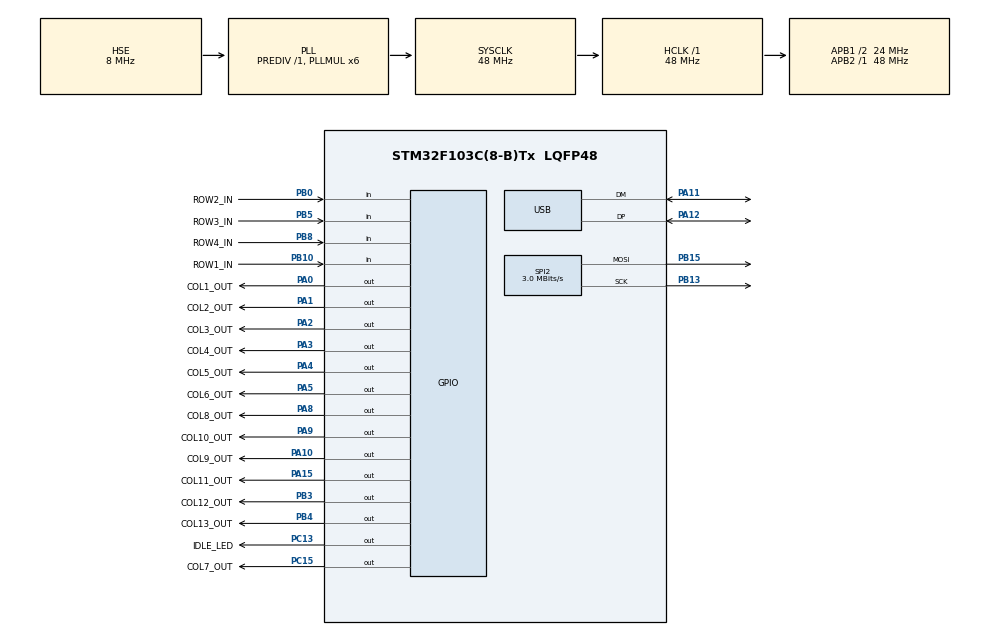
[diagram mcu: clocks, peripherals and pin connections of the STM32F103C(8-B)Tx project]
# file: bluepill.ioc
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Mcu.Family=STM32F1
Dma.SPI2_TX.0.MemInc=DMA_MINC_ENABLE
USB_DEVICE.CLASS_NAME_FS=HID
NVIC.DMA1_Channel5_IRQn=true\:0\:0\:false\:false\:true\:false\:true
PB10.GPIO_PuPd=GPIO_PULLDOWN
SPI2.VirtualType=VM_MASTER
PA11.Mode=Device
PB0.GPIO_Label=ROW2_IN
PB13.Signal=SPI2_SCK
PB15.Signal=SPI2_MOSI
PC15-OSC32_OUT.GPIO_Label=COL7_OUT
Dma.SPI2_TX.0.Instance=DMA1_Channel5
RCC.SYSCLKSource=RCC_SYSCLKSOURCE_PLLCLK
ProjectManager.StackSize=0x400
PD1-OSC_OUT.Signal=RCC_OSC_OUT
Dma.SPI2_TX.0.MemDataAlignment=DMA_MDATAALIGN_BYTE
USB_DEVICE.MANUFACTURER_STRING=Disciplined Design
USB_DEVICE.PID_HID_FS=0x0666
PA15.GPIO_Label=COL11_OUT
PA12.Signal=USB_DP
SPI2.CLKPolarity=SPI_POLARITY_LOW
RCC.HCLKFreq_Value=48000000
RCC.APB2TimFreq_Value=48000000
Dma.SPI2_TX.0.Mode=DMA_NORMAL
RCC.AHBFreq_Value=48000000
SPI2.BaudRatePrescaler=SPI_BAUDRATEPRESCALER_8
RCC.PLLMUL=RCC_PLL_MUL6
PA14.Mode=Serial_Wire
PA10.GPIO_Label=COL9_OUT
SPI2.CalculateBaudRate=3.0 MBits/s
PA8.Signal=GPIO_Output
Mcu.Package=LQFP48
SPI2.Mode=SPI_MODE_MASTER
PA2.GPIO_Label=COL3_OUT
PA10.Signal=GPIO_Output
PA15.Signal=GPIO_Output
Dma.SPI2_TX.0.PeriphInc=DMA_PINC_DISABLE
PB5.GPIO_Label=ROW3_IN
RCC.APB1TimFreq_Value=48000000
SPI2.Direction=SPI_DIRECTION_2LINES
PB13.Mode=TX_Only_Simplex_Unidirect_Master
Dma.Request0=SPI2_TX
PA4.GPIO_Label=COL5_OUT
PB4.Signal=GPIO_Output
PA3.Signal=GPIO_Output
PB3.GPIO_Label=COL12_OUT
PD1-OSC_OUT.Mode=HSE-External-Oscillator
USB_DEVICE.VirtualModeFS=Hid_FS
PA9.GPIO_Label=COL10_OUT
PB8.GPIO_PuPd=GPIO_PULLDOWN
USB_DEVICE.PRODUCT_STRING_HID_FS=DD Keyboard
PC13-TAMPER-RTC.Signal=GPIO_Output
PD0-OSC_IN.Signal=RCC_OSC_IN
RCC.APB1CLKDivider=RCC_HCLK_DIV2
PA0-WKUP.GPIO_Label=COL1_OUT
PA0-WKUP.Signal=GPIO_Output
PA13.Signal=SYS_JTMS-SWDIO
PB8.GPIO_Label=ROW4_IN
PA8.GPIO_Label=COL8_OUT
USB_DEVICE.VID=0xFEED
ProjectManager.TargetToolchain=Makefile
PB10.GPIO_Label=ROW1_IN
PA9.Signal=GPIO_Output
RCC.USBFreq_Value=48000000
PC15-OSC32_OUT.Signal=GPIO_Output
PA1.Signal=GPIO_Output
PD0-OSC_IN.Mode=HSE-External-Oscillator
PB10.Signal=GPIO_Input
PA5.Signal=GPIO_Output
board=bluepill
PC13-TAMPER-RTC.GPIO_Label=IDLE_LED
PB15.Mode=TX_Only_Simplex_Unidirect_Master
VP_USB_DEVICE_VS_USB_DEVICE_HID_FS.Mode=HID_FS
RCC.APB2Freq_Value=48000000
PB4.GPIO_Label=COL13_OUT
Dma.SPI2_TX.0.PeriphDataAlignment=DMA_PDATAALIGN_BYTE
NVIC.USB_LP_CAN1_RX0_IRQn=true\:0\:0\:false\:false\:true\:false\:true
PA1.GPIO_Label=COL2_OUT
PA13.Mode=Serial_Wire
Mcu.Name=STM32F103C(8-B)Tx
PA2.Signal=GPIO_Output
PB3.Signal=GPIO_Output
PA4.Signal=GPIO_Output
Dma.SPI2_TX.0.Priority=DMA_PRIORITY_HIGH
RCC.SYSCLKFreq_VALUE=48000000
PB5.Signal=GPIO_Input
PA12.Mode=Device
PA5.GPIO_Label=COL6_OUT
PB5.GPIO_PuPd=GPIO_PULLDOWN
PA11.Signal=USB_DM
PA14.Signal=SYS_JTCK-SWCLK
ProjectManager.HeapSize=0x200
NVIC.PriorityGroup=NVIC_PRIORITYGROUP_4
PB8.Signal=GPIO_Input
Dma.SPI2_TX.0.Direction=DMA_MEMORY_TO_PERIPH
RCC.APB1Freq_Value=24000000
PB0.Signal=GPIO_Input
USB_DEVICE.VirtualMode=Hid
PB0.GPIO_PuPd=GPIO_PULLDOWN
PA3.GPIO_Label=COL4_OUT

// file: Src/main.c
/* USER CODE BEGIN Header */
/**
  ******************************************************************************
  * @file           : main.c
  * @brief          : Main program body
  ******************************************************************************
  * @attention
  *
  * <h2><center>&copy; Copyright (c) 2019 STMicroelectronics.
  * All rights reserved.</center></h2>
  *
  * This software component is licensed by ST under BSD 3-Clause license,
  * the "License"; You may not use this file except in compliance with the
  * License. You may obtain a copy of the License at:
  *                        opensource.org/licenses/BSD-3-Clause
  *
  ******************************************************************************
  */
/* USER CODE END Header */
#include "main.h"
#include "usb_device.h"

/* USER CODE BEGIN Includes */
#include "esm/esm.h"
/* USER CODE END Includes */

SPI_HandleTypeDef hspi2;
DMA_HandleTypeDef hdma_spi2_tx;

/* USER CODE BEGIN PV */
/* Private variables ---------------------------------------------------------*/

/* USER CODE END PV */

void SystemClock_Config(void);
static void MX_GPIO_Init(void);
static void MX_DMA_Init(void);
static void MX_SPI2_Init(void);
/* USER CODE BEGIN PFP */
/* Private function prototypes -----------------------------------------------*/

/* USER CODE END PFP */

int main(void)
{

  /* MCU Configuration--------------------------------------------------------*/

  /* Reset of all peripherals, Initializes the Flash interface and the Systick. */
  HAL_Init();

  /* USER CODE BEGIN Init */
  __HAL_RCC_USB_CLK_DISABLE();
  /* USER CODE END Init */

  /* Configure the system clock */
  SystemClock_Config();

  /* Initialize all configured peripherals */
  MX_GPIO_Init();
  MX_DMA_Init();
  MX_USB_DEVICE_Init();
  MX_SPI2_Init();

  /* Infinite loop */
  /* USER CODE BEGIN WHILE */
  while (1)
  {
	  esm_process();
    /* USER CODE END WHILE */

  }
}

void SystemClock_Config(void)
{
  RCC_OscInitTypeDef RCC_OscInitStruct = {0};
  RCC_ClkInitTypeDef RCC_ClkInitStruct = {0};
  RCC_PeriphCLKInitTypeDef PeriphClkInit = {0};

  /** Initializes the RCC Oscillators according to the specified parameters
  * in the RCC_OscInitTypeDef structure.
  */
  RCC_OscInitStruct.OscillatorType = RCC_OSCILLATORTYPE_HSE;
  RCC_OscInitStruct.HSEState = RCC_HSE_ON;
  RCC_OscInitStruct.HSEPredivValue = RCC_HSE_PREDIV_DIV1;
  RCC_OscInitStruct.HSIState = RCC_HSI_ON;
  RCC_OscInitStruct.PLL.PLLState = RCC_PLL_ON;
  RCC_OscInitStruct.PLL.PLLSource = RCC_PLLSOURCE_HSE;
  RCC_OscInitStruct.PLL.PLLMUL = RCC_PLL_MUL6;
  if (HAL_RCC_OscConfig(&RCC_OscInitStruct) != HAL_OK)
  {
    Error_Handler();
  }
  /** Initializes the CPU, AHB and APB buses clocks
  */
  RCC_ClkInitStruct.ClockType = RCC_CLOCKTYPE_HCLK|RCC_CLOCKTYPE_SYSCLK
                              |RCC_CLOCKTYPE_PCLK1|RCC_CLOCKTYPE_PCLK2;
  RCC_ClkInitStruct.SYSCLKSource = RCC_SYSCLKSOURCE_PLLCLK;
  RCC_ClkInitStruct.AHBCLKDivider = RCC_SYSCLK_DIV1;
  RCC_ClkInitStruct.APB1CLKDivider = RCC_HCLK_DIV2;
  RCC_ClkInitStruct.APB2CLKDivider = RCC_HCLK_DIV1;

  if (HAL_RCC_ClockConfig(&RCC_ClkInitStruct, FLASH_LATENCY_1) != HAL_OK)
  {
    Error_Handler();
  }
  PeriphClkInit.PeriphClockSelection = RCC_PERIPHCLK_USB;
  PeriphClkInit.UsbClockSelection = RCC_USBCLKSOURCE_PLL;
  if (HAL_RCCEx_PeriphCLKConfig(&PeriphClkInit) != HAL_OK)
  {
    Error_Handler();
  }
}

static void MX_SPI2_Init(void)
{

  /* SPI2 parameter configuration*/
  hspi2.Instance = SPI2;
  hspi2.Init.Mode = SPI_MODE_MASTER;
  hspi2.Init.Direction = SPI_DIRECTION_2LINES;
  hspi2.Init.DataSize = SPI_DATASIZE_8BIT;
  hspi2.Init.CLKPolarity = SPI_POLARITY_LOW;
  hspi2.Init.CLKPhase = SPI_PHASE_1EDGE;
  hspi2.Init.NSS = SPI_NSS_SOFT;
  hspi2.Init.BaudRatePrescaler = SPI_BAUDRATEPRESCALER_8;
  hspi2.Init.FirstBit = SPI_FIRSTBIT_MSB;
  hspi2.Init.TIMode = SPI_TIMODE_DISABLE;
  hspi2.Init.CRCCalculation = SPI_CRCCALCULATION_DISABLE;
  hspi2.Init.CRCPolynomial = 10;
  if (HAL_SPI_Init(&hspi2) != HAL_OK)
  {
    Error_Handler();
  }
  /* USER CODE BEGIN SPI2_Init 2 */
  // This is a workaround - for some reason first DMA TX is wrong
  uint8_t data[100] = {0};
  HAL_SPI_Transmit(&hspi2, data, sizeof(data), 100);
  /* USER CODE END SPI2_Init 2 */

}

static void MX_DMA_Init(void)
{

  /* DMA controller clock enable */
  __HAL_RCC_DMA1_CLK_ENABLE();

  /* DMA interrupt init */
  /* DMA1_Channel5_IRQn interrupt configuration */
  HAL_NVIC_SetPriority(DMA1_Channel5_IRQn, 0, 0);
  HAL_NVIC_EnableIRQ(DMA1_Channel5_IRQn);

}

static void MX_GPIO_Init(void)
{
  GPIO_InitTypeDef GPIO_InitStruct = {0};

  /* GPIO Ports Clock Enable */
  __HAL_RCC_GPIOC_CLK_ENABLE();
  __HAL_RCC_GPIOD_CLK_ENABLE();
  __HAL_RCC_GPIOA_CLK_ENABLE();
  __HAL_RCC_GPIOB_CLK_ENABLE();

  /*Configure GPIO pin Output Level */
  HAL_GPIO_WritePin(GPIOC, IDLE_LED_Pin|COL7_OUT_Pin, GPIO_PIN_RESET);

  /*Configure GPIO pin Output Level */
  HAL_GPIO_WritePin(GPIOA, COL1_OUT_Pin|COL2_OUT_Pin|COL3_OUT_Pin|COL4_OUT_Pin
                          |COL5_OUT_Pin|COL6_OUT_Pin|COL8_OUT_Pin|COL10_OUT_Pin
                          |COL9_OUT_Pin|COL11_OUT_Pin, GPIO_PIN_RESET);

  /*Configure GPIO pin Output Level */
  HAL_GPIO_WritePin(GPIOB, COL12_OUT_Pin|COL13_OUT_Pin, GPIO_PIN_RESET);

  /*Configure GPIO pins : IDLE_LED_Pin COL7_OUT_Pin */
  GPIO_InitStruct.Pin = IDLE_LED_Pin|COL7_OUT_Pin;
  GPIO_InitStruct.Mode = GPIO_MODE_OUTPUT_PP;
  GPIO_InitStruct.Pull = GPIO_NOPULL;
  GPIO_InitStruct.Speed = GPIO_SPEED_FREQ_LOW;
  HAL_GPIO_Init(GPIOC, &GPIO_InitStruct);

  /*Configure GPIO pins : COL1_OUT_Pin COL2_OUT_Pin COL3_OUT_Pin COL4_OUT_Pin
                           COL5_OUT_Pin COL6_OUT_Pin COL8_OUT_Pin COL10_OUT_Pin
                           COL9_OUT_Pin COL11_OUT_Pin */
  GPIO_InitStruct.Pin = COL1_OUT_Pin|COL2_OUT_Pin|COL3_OUT_Pin|COL4_OUT_Pin
                          |COL5_OUT_Pin|COL6_OUT_Pin|COL8_OUT_Pin|COL10_OUT_Pin
                          |COL9_OUT_Pin|COL11_OUT_Pin;
  GPIO_InitStruct.Mode = GPIO_MODE_OUTPUT_PP;
  GPIO_InitStruct.Pull = GPIO_NOPULL;
  GPIO_InitStruct.Speed = GPIO_SPEED_FREQ_LOW;
  HAL_GPIO_Init(GPIOA, &GPIO_InitStruct);

  /*Configure GPIO pins : ROW2_IN_Pin ROW1_IN_Pin ROW3_IN_Pin ROW4_IN_Pin */
  GPIO_InitStruct.Pin = ROW2_IN_Pin|ROW1_IN_Pin|ROW3_IN_Pin|ROW4_IN_Pin;
  GPIO_InitStruct.Mode = GPIO_MODE_INPUT;
  GPIO_InitStruct.Pull = GPIO_PULLDOWN;
  HAL_GPIO_Init(GPIOB, &GPIO_InitStruct);

  /*Configure GPIO pins : COL12_OUT_Pin COL13_OUT_Pin */
  GPIO_InitStruct.Pin = COL12_OUT_Pin|COL13_OUT_Pin;
  GPIO_InitStruct.Mode = GPIO_MODE_OUTPUT_PP;
  GPIO_InitStruct.Pull = GPIO_NOPULL;
  GPIO_InitStruct.Speed = GPIO_SPEED_FREQ_LOW;
  HAL_GPIO_Init(GPIOB, &GPIO_InitStruct);

}

void Error_Handler(void)
{
  while(1)
  {
  }
}

/************************ (C) COPYRIGHT STMicroelectronics *****END OF FILE****/
